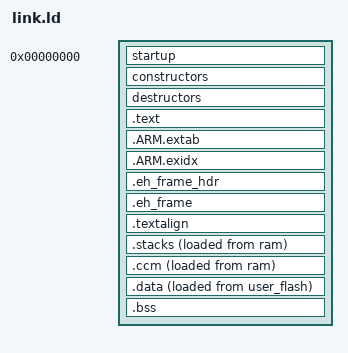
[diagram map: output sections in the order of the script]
/*
    ChibiOS/RT - Copyright (C) 2006,2007,2008,2009,2010,
                 2011,2012,2013 Giovanni Di Sirio.

    This file is part of ChibiOS/RT.

    ChibiOS/RT is free software; you can redistribute it and/or modify
    it under the terms of the GNU General Public License as published by
    the Free Software Foundation; either version 3 of the License, or
    (at your option) any later version.

    ChibiOS/RT is distributed in the hope that it will be useful,
    but WITHOUT ANY WARRANTY; without even the implied warranty of
    MERCHANTABILITY or FITNESS FOR A PARTICULAR PURPOSE.  See the
    GNU General Public License for more details.

    You should have received a copy of the GNU General Public License
    along with this program.  If not, see <http://www.gnu.org/licenses/>.
*/

INCLUDE ../common/STM32F303xC_common.ld

ENTRY(Reset_Handler)

SECTIONS
{
    . = 0;
    _text = .;

    startup : ALIGN(16) SUBALIGN(16)
    {
        KEEP(*(vectors))
    } > user_flash

    constructors : ALIGN(4) SUBALIGN(4)
    {
        PROVIDE(__init_array_start = .);
        KEEP(*(SORT(.init_array.*)))
        KEEP(*(.init_array))
        PROVIDE(__init_array_end = .);
    } > user_flash

    destructors : ALIGN(4) SUBALIGN(4)
    {
        PROVIDE(__fini_array_start = .);
        KEEP(*(.fini_array))
        KEEP(*(SORT(.fini_array.*)))
        PROVIDE(__fini_array_end = .);
    } > user_flash

    .text : ALIGN(16) SUBALIGN(16)
    {
        *(.text.startup.*)
        *(.text)
        *(.text.*)
        *(.rodata)
        *(.rodata.*)
        *(.glue_7t)
        *(.glue_7)
        *(.gcc*)
    } > user_flash

    .ARM.extab :
    {
        *(.ARM.extab* .gnu.linkonce.armextab.*)
    } > user_flash

    .ARM.exidx : {
        PROVIDE(__exidx_start = .);
        *(.ARM.exidx* .gnu.linkonce.armexidx.*)
        PROVIDE(__exidx_end = .);
     } > user_flash

    .eh_frame_hdr :
    {
        *(.eh_frame_hdr)
    } > user_flash

    .eh_frame : ONLY_IF_RO
    {
        *(.eh_frame)
    } > user_flash
    
    .textalign : ONLY_IF_RO
    {
        . = ALIGN(8);
    } > user_flash

    . = ALIGN(4);
    _etext = .;
    _textdata = _etext;

    .stacks :
    {
        . = ALIGN(8);
        __main_stack_base__ = .;
        . += __main_stack_size__;
        . = ALIGN(8);
        __main_stack_end__ = .;
        __process_stack_base__ = .;
        __main_thread_stack_base__ = .;
        . += __process_stack_size__;
        . = ALIGN(8);
        __process_stack_end__ = .;
        __main_thread_stack_end__ = .;
    } > ccmram AT > ram
    
    .ccm (NOLOAD) :
    {
        PROVIDE(_cmm_start = .);
        . = ALIGN(4);
        *(.stacks)
        . = ALIGN(8);
        *(.stacks.*)
        . = ALIGN(8);
        *(.ccm)
        . = ALIGN(4);
        *(.ccm.*)
        . = ALIGN(4);
        *(.bss.mainthread.*)
        . = ALIGN(4);
        *(.bss._idle_thread_wa)
        . = ALIGN(4);
        *(.bss.rlist)
        . = ALIGN(4);
        *(.bss.vtlist)
        . = ALIGN(4);
        *(.bss.endmem)
        . = ALIGN(4);
        *(.bss.nextmem)
        . = ALIGN(4);
        *(.bss.default_heap)
        . = ALIGN(4);
        PROVIDE(_cmm_end = .);
    } > ccmram AT > ram

    .data :
    {
        . = ALIGN(4);
        PROVIDE(_data = .);
        *(.data)
        . = ALIGN(4);
        *(.data.*)
        . = ALIGN(4);
        *(.ramtext)
        . = ALIGN(4);
        PROVIDE(_edata = .);
    } > ram AT > user_flash

    .bss :
    {
        . = ALIGN(4);
        PROVIDE(_bss_start = .);
        *(.bss)
        . = ALIGN(4);
        *(.bss.*)
        . = ALIGN(4);
        *(COMMON)
        . = ALIGN(4);
        PROVIDE(_bss_end = .);
    } > ram    
}

PROVIDE(end = .);
_end            = .;

__heap_base__   = _end;
__heap_end__    = __ram_end__;
